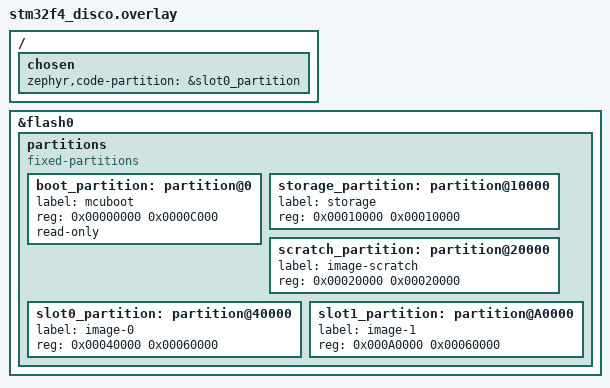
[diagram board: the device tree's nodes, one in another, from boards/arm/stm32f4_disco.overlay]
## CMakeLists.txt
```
cmake_minimum_required(VERSION 3.20.0)

find_package(Zephyr REQUIRED HINTS $ENV{ZEPHYR_BASE})
project(zbox)

if(NOT (DEFINED SYSBUILD))
  message(FATAL_ERROR "This project must be built with sysbuild.")
endif()

set(SRC_DIR "src")
#set(INCLUDE_DIRS
#    "${SRC_DIR}/lib"
#    "${SRC_DIR}/external"
#)

# nanopb stuff
#list(APPEND CMAKE_MODULE_PATH ${ZEPHYR_BASE}/modules/nanopb)
#include(nanopb)

# List 'regular' source files
set(SRC_FILES
    "${SRC_DIR}/main.cpp"
)

#target_include_directories(app PRIVATE ${INCLUDE_DIRS})
#zephyr_nanopb_sources(app proto/protocol.proto)
target_sources(app PRIVATE ${SRC_FILES})
```

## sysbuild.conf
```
SB_CONFIG_BOOTLOADER_MCUBOOT=y

# This key was generated according to documentation on mcuboot.md and is currently
# being in a different git private repository (github.com/TSMotter/privkeys).
# This option is currently being set in command line during build
# The actual west command used to build can be checked at `bbuild.sh` script
#SB_CONFIG_BOOT_SIGNATURE_KEY_FILE=\""$(pwd)/../privkeys/zbox-root-rsa-2048.pem"\"
```

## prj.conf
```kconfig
CONFIG_CPP=y
CONFIG_PRINTK=y
CONFIG_LOG=y
CONFIG_LOG_PRINTK=y


# Ensure an MCUboot-compatible binary is generated.
CONFIG_BOOTLOADER_MCUBOOT=y

# Enable MCUmgr and dependencies.
CONFIG_NET_BUF=y
CONFIG_ZCBOR=y
CONFIG_CRC=y
CONFIG_MCUMGR=y
CONFIG_STREAM_FLASH=y
CONFIG_FLASH_MAP=y

# Enable flash operations.
CONFIG_FLASH=y
# Required by the `taskstat` command.
CONFIG_THREAD_MONITOR=y
# Support for taskstat command
CONFIG_MCUMGR_GRP_OS_TASKSTAT=y
# Enable statistics and statistic names.
CONFIG_STATS=y
CONFIG_STATS_NAMES=y
# Enable most core commands.
CONFIG_FLASH=y
CONFIG_IMG_MANAGER=y
CONFIG_MCUMGR_GRP_IMG=y
CONFIG_MCUMGR_GRP_OS=y
CONFIG_MCUMGR_GRP_STAT=y
# Enable the serial MCUmgr transport.
CONFIG_BASE64=y
CONFIG_MCUMGR_TRANSPORT_UART=y
CONFIG_CONSOLE=y
```

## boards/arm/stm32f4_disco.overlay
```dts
/ {
    chosen {
        zephyr,code-partition = &slot0_partition;
    };
};

&flash0 {
    status = "okay";
    partitions {
        compatible = "fixed-partitions";
        #address-cells = <1>;
        #size-cells = <1>;

        /*
            Bootloader
            Sectors 0 (16kB) + 1 (16kB) + 2 (16kB) = 48kB
        */
        boot_partition: partition@0 {
            label = "mcuboot";
            reg = <0x00000000 0x0000C000>;
            read-only;
        };

        /*
            Unused
            Sector 3 (16kB) = 16kB
        */

        /*
            Storage
            Sector 4 (64kB) = 64kB
        */
        storage_partition: partition@10000 {
            label = "storage";
            reg = <0x00010000 0x00010000>;
        };

        /*
            Scratch
            Sector 5 (128kB) = 128kB
        */
        scratch_partition: partition@20000 {
               label = "image-scratch";
               reg = <0x00020000 0x00020000>;
        };

        /*
            Slot 0
            Sectors 6 (128kB) + 7 (128kB) + 8 (128kB) = 384kB
        */
        slot0_partition: partition@40000 {
            label = "image-0";
            reg = <0x00040000 0x00060000>;
        };

        /*
            Slot 1
            Sectors 9 (128kB) + 10 (128kB) + 11 (128kB) = 384kB
        */
        slot1_partition: partition@A0000 {
            label = "image-1";
            reg = <0x000A0000 0x00060000>;
        };
    };
};
```

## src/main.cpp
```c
#include <zephyr/kernel.h>
#include <zephyr/drivers/gpio.h>
#include <zephyr/logging/log.h>

#include <zephyr/stats/stats.h>
#ifdef CONFIG_MCUMGR_GRP_STAT
#include <zephyr/mgmt/mcumgr/grp/stat_mgmt/stat_mgmt.h>
#endif

/***************************************************************************************************
 * LOGs
 ***************************************************************************************************/
#define LOG_LEVEL LOG_LEVEL_DBG
LOG_MODULE_REGISTER(zbox);


/***************************************************************************************************
 * SMP Server Statistics Management
 ***************************************************************************************************/
// Define an example stats group
STATS_SECT_START(smp_server_stats)
STATS_SECT_ENTRY(counter_stat)
STATS_SECT_END;

// Assign a name to the `counter_stat` stat.
STATS_NAME_START(smp_server_stats)
STATS_NAME(smp_server_stats, counter_stat)
STATS_NAME_END(smp_server_stats);

// Define an instance of the stats group.
STATS_SECT_DECL(smp_server_stats) smp_server_stats;

/***************************************************************************************************
 * Switch between GREEN_BIN and BLUE_BIN
 ***************************************************************************************************/
// Choose one LED to blink
#define GREEN_BIN
// #define BLUE_BIN

#ifdef GREEN_BIN

#define GREEN_LED_NODE DT_NODELABEL(green_led_4)
static const struct gpio_dt_spec led_dt_spec = GPIO_DT_SPEC_GET_OR(GREEN_LED_NODE, gpios, {0});

#elif defined(BLUE_BIN)

#define BLUE_LED_NODE DT_NODELABEL(blue_led_6)
static const struct gpio_dt_spec led_dt_spec = GPIO_DT_SPEC_GET_OR(BLUE_LED_NODE, gpios, {0});

#endif

/* 1000 msec = 1 sec */
#define SLEEP_TIME_MS 1000

int main(void)
{
    int rc = STATS_INIT_AND_REG(smp_server_stats, STATS_SIZE_32, "smp_server_stats");

    if (rc < 0)
    {
        LOG_ERR("Error initializing stats system [%d]", rc);
        return 0;
    }

    if (!gpio_is_ready_dt(&led_dt_spec))
    {
        return 0;
    }

    rc = gpio_pin_configure_dt(&led_dt_spec, GPIO_OUTPUT_ACTIVE);
    if (rc < 0)
    {
        return 0;
    }

    while (1)
    {
        rc = gpio_pin_toggle_dt(&led_dt_spec);
        if (rc < 0)
        {
            return 0;
        }
        k_msleep(SLEEP_TIME_MS);
        STATS_INC(smp_server_stats, counter_stat);
    }
    return 0;
}
```
